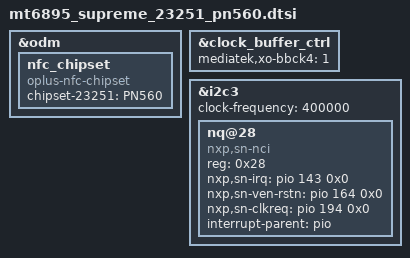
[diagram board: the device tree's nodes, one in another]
/**********************************************************************************
* Copyright (c)  2008-2020  Guangdong oplus Mobile Comm Corp., Ltd
*
***********************************************************************************/
&odm {
	nfc_chipset:nfc_chipset {
		compatible = "oplus-nfc-chipset";
		chipset-23251 = "PN560";
	};
};

&clock_buffer_ctrl {
	mediatek,xo-bbck4 = <1>;
};

&i2c3 {
       status = "okay";
       clock-frequency = <400000>;
       nq@28 {
               compatible = "nxp,sn-nci";
               reg = <0x28>;
               nxp,sn-irq = <&pio 143 0x0>;
               nxp,sn-ven-rstn = <&pio 164 0x0>;
               nxp,sn-clkreq = <&pio 194 0x0>;
               interrupt-parent = <&pio>;
       };
};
